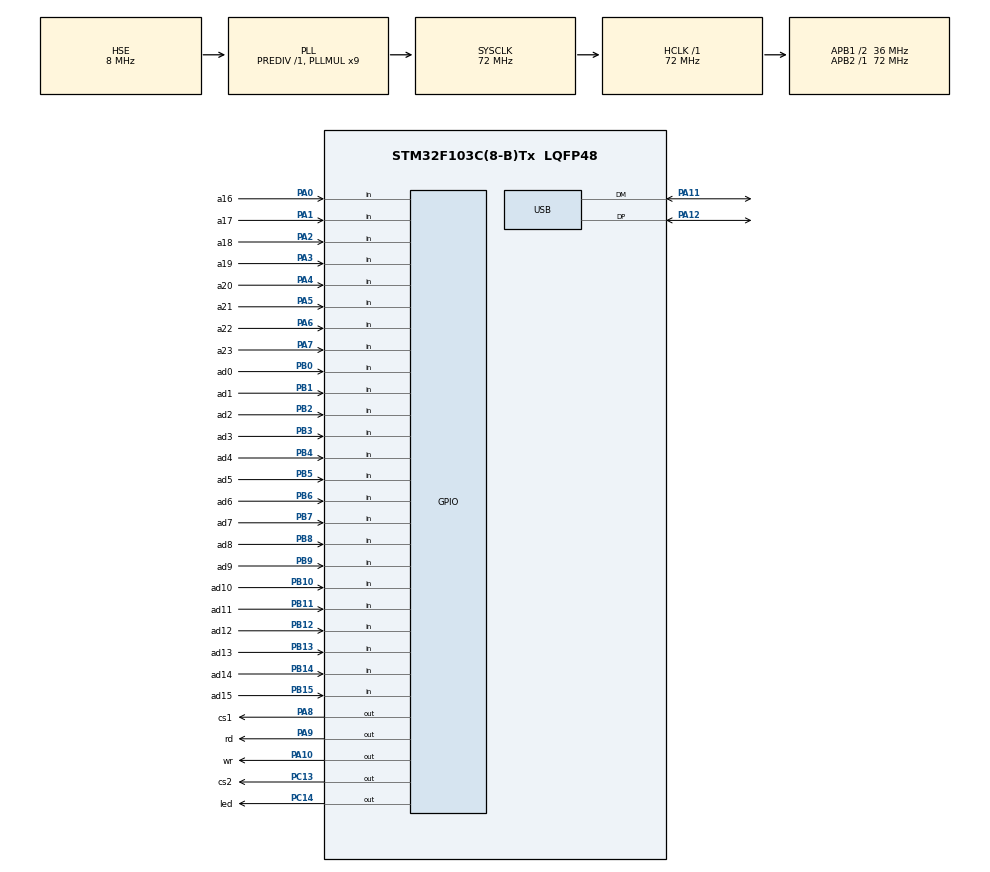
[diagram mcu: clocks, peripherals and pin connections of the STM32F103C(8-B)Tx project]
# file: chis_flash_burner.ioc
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Mcu.Family=STM32F1
Mcu.Name=STM32F103C(8-B)Tx
Mcu.Package=LQFP48
NVIC.PriorityGroup=NVIC_PRIORITYGROUP_4
NVIC.USB_LP_CAN1_RX0_IRQn=true\:0\:0\:false\:false\:true\:false\:true\:true
PA0-WKUP.GPIO_Label=a16
PA0-WKUP.GPIO_PuPd=GPIO_PULLUP
PA0-WKUP.Signal=GPIO_Input
PA1.GPIO_Label=a17
PA1.GPIO_PuPd=GPIO_PULLUP
PA1.Signal=GPIO_Input
PA10.GPIO_Label=wr
PA10.GPIO_PuPd=GPIO_PULLUP
PA10.GPIO_Speed=GPIO_SPEED_FREQ_HIGH
PA10.PinState=GPIO_PIN_SET
PA10.Signal=GPIO_Output
PA11.Mode=Device
PA11.Signal=USB_DM
PA12.Mode=Device
PA12.Signal=USB_DP
PA13.Mode=Serial_Wire
PA13.Signal=SYS_JTMS-SWDIO
PA14.Mode=Serial_Wire
PA14.Signal=SYS_JTCK-SWCLK
PA2.GPIO_Label=a18
PA2.GPIO_PuPd=GPIO_PULLUP
PA2.Signal=GPIO_Input
PA3.GPIO_Label=a19
PA3.GPIO_PuPd=GPIO_PULLUP
PA3.Signal=GPIO_Input
PA4.GPIO_Label=a20
PA4.GPIO_PuPd=GPIO_PULLUP
PA4.Signal=GPIO_Input
PA5.GPIO_Label=a21
PA5.GPIO_PuPd=GPIO_PULLUP
PA5.Signal=GPIO_Input
PA6.GPIO_Label=a22
PA6.GPIO_PuPd=GPIO_PULLUP
PA6.Signal=GPIO_Input
PA7.GPIO_Label=a23
PA7.GPIO_PuPd=GPIO_PULLUP
PA7.Signal=GPIO_Input
PA8.GPIO_Label=cs1
PA8.GPIO_ModeDefaultOutputPP=GPIO_MODE_OUTPUT_PP
PA8.GPIO_PuPd=GPIO_PULLUP
PA8.GPIO_Speed=GPIO_SPEED_FREQ_HIGH
PA8.PinState=GPIO_PIN_SET
PA8.Signal=GPIO_Output
PA9.GPIO_Label=rd
PA9.GPIO_PuPd=GPIO_PULLUP
PA9.GPIO_Speed=GPIO_SPEED_FREQ_HIGH
PA9.PinState=GPIO_PIN_SET
PA9.Signal=GPIO_Output
PB0.GPIO_Label=ad0
PB0.GPIO_PuPd=GPIO_PULLUP
PB0.Signal=GPIO_Input
PB1.GPIO_Label=ad1
PB1.GPIO_PuPd=GPIO_PULLUP
PB1.Signal=GPIO_Input
PB10.GPIO_Label=ad10
PB10.GPIO_PuPd=GPIO_PULLUP
PB10.Signal=GPIO_Input
PB11.GPIO_Label=ad11
PB11.GPIO_PuPd=GPIO_PULLUP
PB11.Signal=GPIO_Input
PB12.GPIO_Label=ad12
PB12.GPIO_PuPd=GPIO_PULLUP
PB12.Signal=GPIO_Input
PB13.GPIO_Label=ad13
PB13.GPIO_PuPd=GPIO_PULLUP
PB13.Signal=GPIO_Input
PB14.GPIO_Label=ad14
PB14.GPIO_PuPd=GPIO_PULLUP
PB14.Signal=GPIO_Input
PB15.GPIO_Label=ad15
PB15.GPIO_PuPd=GPIO_PULLUP
PB15.Signal=GPIO_Input
PB2.GPIO_Label=ad2
PB2.GPIO_PuPd=GPIO_PULLUP
PB2.Signal=GPIO_Input
PB3.GPIO_Label=ad3
PB3.GPIO_PuPd=GPIO_PULLUP
PB3.Signal=GPIO_Input
PB4.GPIO_Label=ad4
PB4.GPIO_PuPd=GPIO_PULLUP
PB4.Signal=GPIO_Input
PB5.GPIO_Label=ad5
PB5.GPIO_PuPd=GPIO_PULLUP
PB5.Signal=GPIO_Input
PB6.GPIO_Label=ad6
PB6.GPIO_PuPd=GPIO_PULLUP
PB6.Signal=GPIO_Input
PB7.GPIO_Label=ad7
PB7.GPIO_PuPd=GPIO_PULLUP
PB7.Signal=GPIO_Input
PB8.GPIO_Label=ad8
PB8.GPIO_PuPd=GPIO_PULLUP
PB8.Signal=GPIO_Input
PB9.GPIO_Label=ad9
PB9.GPIO_PuPd=GPIO_PULLUP
PB9.Signal=GPIO_Input
PC13-TAMPER-RTC.GPIO_Label=cs2
PC13-TAMPER-RTC.GPIO_PuPd=GPIO_PULLUP
PC13-TAMPER-RTC.GPIO_Speed=GPIO_SPEED_FREQ_HIGH
PC13-TAMPER-RTC.PinState=GPIO_PIN_SET
PC13-TAMPER-RTC.Signal=GPIO_Output
PC14-OSC32_IN.GPIO_Label=led
PC14-OSC32_IN.GPIO_ModeDefaultOutputPP=GPIO_MODE_OUTPUT_PP
PC14-OSC32_IN.GPIO_PuPd=GPIO_PULLUP
PC14-OSC32_IN.GPIO_Speed=GPIO_SPEED_FREQ_HIGH
PC14-OSC32_IN.PinState=GPIO_PIN_SET
PC14-OSC32_IN.Signal=GPIO_Output
PD0-OSC_IN.Mode=HSE-External-Oscillator
PD0-OSC_IN.Signal=RCC_OSC_IN
PD1-OSC_OUT.Mode=HSE-External-Oscillator
PD1-OSC_OUT.Signal=RCC_OSC_OUT
ProjectManager.HeapSize=0x200
ProjectManager.StackSize=0x400
ProjectManager.TargetToolchain=STM32CubeIDE
RCC.AHBFreq_Value=72000000
RCC.APB1CLKDivider=RCC_HCLK_DIV2
RCC.APB1Freq_Value=36000000
RCC.APB1TimFreq_Value=72000000
RCC.APB2Freq_Value=72000000
RCC.APB2TimFreq_Value=72000000
RCC.HCLKFreq_Value=72000000
RCC.PLLMUL=RCC_PLL_MUL9
RCC.PLLSourceVirtual=RCC_PLLSOURCE_HSE
RCC.SYSCLKFreq_VALUE=72000000
RCC.SYSCLKSource=RCC_SYSCLKSOURCE_PLLCLK
RCC.USBFreq_Value=48000000
RCC.USBPrescaler=RCC_USBCLKSOURCE_PLL_DIV1_5
USB_DEVICE.CLASS_NAME_FS=CDC
USB_DEVICE.MANUFACTURER_STRING=CNY Industry
USB_DEVICE.PID_CDC_FS=0x0721
USB_DEVICE.PRODUCT_STRING_CDC_FS=GBA Burner for ChisFlash
USB_DEVICE.VID=0x0483
USB_DEVICE.VirtualMode=Cdc
USB_DEVICE.VirtualModeFS=Cdc_FS
VP_USB_DEVICE_VS_USB_DEVICE_CDC_FS.Mode=CDC_FS
board=custom

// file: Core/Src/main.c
/* USER CODE BEGIN Header */
/**
 ******************************************************************************
 * @file           : main.c
 * @brief          : Main program body
 ******************************************************************************
 * @attention
 *
 * Copyright (c) 2024 STMicroelectronics.
 * All rights reserved.
 *
 * This software is licensed under terms that can be found in the LICENSE file
 * in the root directory of this software component.
 * If no LICENSE file comes with this software, it is provided AS-IS.
 *
 ******************************************************************************
 */
/* USER CODE END Header */
#include "main.h"
#include "usb_device.h"

/* USER CODE BEGIN Includes */
#include "cart_adapter.h"
#include "uart.h"
/* USER CODE END Includes */

void SystemClock_Config(void);
static void MX_GPIO_Init(void);

int main(void)
{

  /* MCU Configuration--------------------------------------------------------*/

  /* Reset of all peripherals, Initializes the Flash interface and the Systick. */
  HAL_Init();

  /* Configure the system clock */
  SystemClock_Config();

  /* Initialize all configured peripherals */
  MX_GPIO_Init();
  MX_USB_DEVICE_Init();

  /* Infinite loop */
  while (1)
  {

    /* USER CODE BEGIN 3 */

    uart_cmdHandler();
    // HAL_Delay(1000);
    // HAL_GPIO_WritePin(led_GPIO_Port, led_Pin, 1);
    // HAL_Delay(1000);
    // HAL_GPIO_WritePin(led_GPIO_Port, led_Pin, 0);
  }
  /* USER CODE END 3 */
}

void SystemClock_Config(void)
{
  RCC_OscInitTypeDef RCC_OscInitStruct = {0};
  RCC_ClkInitTypeDef RCC_ClkInitStruct = {0};
  RCC_PeriphCLKInitTypeDef PeriphClkInit = {0};

  /** Initializes the RCC Oscillators according to the specified parameters
  * in the RCC_OscInitTypeDef structure.
  */
  RCC_OscInitStruct.OscillatorType = RCC_OSCILLATORTYPE_HSE;
  RCC_OscInitStruct.HSEState = RCC_HSE_ON;
  RCC_OscInitStruct.HSEPredivValue = RCC_HSE_PREDIV_DIV1;
  RCC_OscInitStruct.HSIState = RCC_HSI_ON;
  RCC_OscInitStruct.PLL.PLLState = RCC_PLL_ON;
  RCC_OscInitStruct.PLL.PLLSource = RCC_PLLSOURCE_HSE;
  RCC_OscInitStruct.PLL.PLLMUL = RCC_PLL_MUL9;
  if (HAL_RCC_OscConfig(&RCC_OscInitStruct) != HAL_OK)
  {
    Error_Handler();
  }

  /** Initializes the CPU, AHB and APB buses clocks
  */
  RCC_ClkInitStruct.ClockType = RCC_CLOCKTYPE_HCLK|RCC_CLOCKTYPE_SYSCLK
                              |RCC_CLOCKTYPE_PCLK1|RCC_CLOCKTYPE_PCLK2;
  RCC_ClkInitStruct.SYSCLKSource = RCC_SYSCLKSOURCE_PLLCLK;
  RCC_ClkInitStruct.AHBCLKDivider = RCC_SYSCLK_DIV1;
  RCC_ClkInitStruct.APB1CLKDivider = RCC_HCLK_DIV2;
  RCC_ClkInitStruct.APB2CLKDivider = RCC_HCLK_DIV1;

  if (HAL_RCC_ClockConfig(&RCC_ClkInitStruct, FLASH_LATENCY_2) != HAL_OK)
  {
    Error_Handler();
  }
  PeriphClkInit.PeriphClockSelection = RCC_PERIPHCLK_USB;
  PeriphClkInit.UsbClockSelection = RCC_USBCLKSOURCE_PLL_DIV1_5;
  if (HAL_RCCEx_PeriphCLKConfig(&PeriphClkInit) != HAL_OK)
  {
    Error_Handler();
  }
}

static void MX_GPIO_Init(void)
{
  GPIO_InitTypeDef GPIO_InitStruct = {0};

  /* GPIO Ports Clock Enable */
  __HAL_RCC_GPIOC_CLK_ENABLE();
  __HAL_RCC_GPIOD_CLK_ENABLE();
  __HAL_RCC_GPIOA_CLK_ENABLE();
  __HAL_RCC_GPIOB_CLK_ENABLE();

  /*Configure GPIO pin Output Level */
  HAL_GPIO_WritePin(GPIOC, cs2_Pin|led_Pin, GPIO_PIN_SET);

  /*Configure GPIO pin Output Level */
  HAL_GPIO_WritePin(GPIOA, cs1_Pin|rd_Pin|wr_Pin, GPIO_PIN_SET);

  /*Configure GPIO pins : cs2_Pin led_Pin */
  GPIO_InitStruct.Pin = cs2_Pin|led_Pin;
  GPIO_InitStruct.Mode = GPIO_MODE_OUTPUT_PP;
  GPIO_InitStruct.Pull = GPIO_PULLUP;
  GPIO_InitStruct.Speed = GPIO_SPEED_FREQ_HIGH;
  HAL_GPIO_Init(GPIOC, &GPIO_InitStruct);

  /*Configure GPIO pins : a16_Pin a17_Pin a18_Pin a19_Pin
                           a20_Pin a21_Pin a22_Pin a23_Pin */
  GPIO_InitStruct.Pin = a16_Pin|a17_Pin|a18_Pin|a19_Pin
                          |a20_Pin|a21_Pin|a22_Pin|a23_Pin;
  GPIO_InitStruct.Mode = GPIO_MODE_INPUT;
  GPIO_InitStruct.Pull = GPIO_PULLUP;
  HAL_GPIO_Init(GPIOA, &GPIO_InitStruct);

  /*Configure GPIO pins : ad0_Pin ad1_Pin ad2_Pin ad10_Pin
                           ad11_Pin ad12_Pin ad13_Pin ad14_Pin
                           ad15_Pin ad3_Pin ad4_Pin ad5_Pin
                           ad6_Pin ad7_Pin ad8_Pin ad9_Pin */
  GPIO_InitStruct.Pin = ad0_Pin|ad1_Pin|ad2_Pin|ad10_Pin
                          |ad11_Pin|ad12_Pin|ad13_Pin|ad14_Pin
                          |ad15_Pin|ad3_Pin|ad4_Pin|ad5_Pin
                          |ad6_Pin|ad7_Pin|ad8_Pin|ad9_Pin;
  GPIO_InitStruct.Mode = GPIO_MODE_INPUT;
  GPIO_InitStruct.Pull = GPIO_PULLUP;
  HAL_GPIO_Init(GPIOB, &GPIO_InitStruct);

  /*Configure GPIO pins : cs1_Pin rd_Pin wr_Pin */
  GPIO_InitStruct.Pin = cs1_Pin|rd_Pin|wr_Pin;
  GPIO_InitStruct.Mode = GPIO_MODE_OUTPUT_PP;
  GPIO_InitStruct.Pull = GPIO_PULLUP;
  GPIO_InitStruct.Speed = GPIO_SPEED_FREQ_HIGH;
  HAL_GPIO_Init(GPIOA, &GPIO_InitStruct);

}

void Error_Handler(void)
{
  __disable_irq();
  while (1)
  {
  }
}
